# CONTROLSS_INPUTXBAR_CONTROLSS_INPUTXBAR register map
Vendor: Texas Instruments
Peripheral module from a debugger description file (folder AM263).
Registers are 8-bit, read-write, reset 0x0 unless marked. A register's access mark holds for its fields unless they carry their own. Offsets are as the file gives them; lines under a group give offsets from that group; [hi:lo] are bit positions; {n}, {i} and the like mark numbered series; 'fields as' and 'values as' point back to an identical list; <NAME> marks a mode.

## CONTROLSS_INPUTXBAR_CONTROLSS_INPUTXBAR
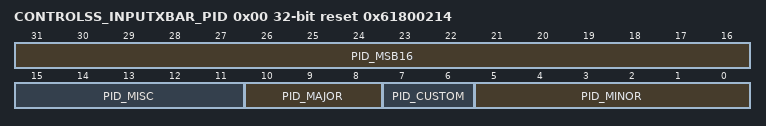
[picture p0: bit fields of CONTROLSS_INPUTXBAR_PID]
0x00 CONTROLSS_INPUTXBAR_PID 32-bit ro reset 0x61800214
  [31:16] PID_MSB16 — Not Defined
  [15:11] PID_MISC — Not Defined
  [10:8] PID_MAJOR — Not Defined
  [7:6] PID_CUSTOM — Not Defined
  [5:0] PID_MINOR — Not Defined
{0x100+0x40*i} CONTROLSS_INPUTXBAR_INPUTXBAR{i}_GSEL size not given (i=0..31)
  [0] GSEL — Select input source Group:0 G0 selected1 G1 selected
{0x104+0x40*i} CONTROLSS_INPUTXBAR_INPUTXBAR{i}_G0 (i=0..31)
  [7:0] SEL — Select input source:0 G0.0 selected..x G0.x selected
{0x108+0x40*i} CONTROLSS_INPUTXBAR_INPUTXBAR{i}_G1 (i=0..31)
  [4:0] SEL — Select input source:0 G1.0 selected..31 G1.31 selected
